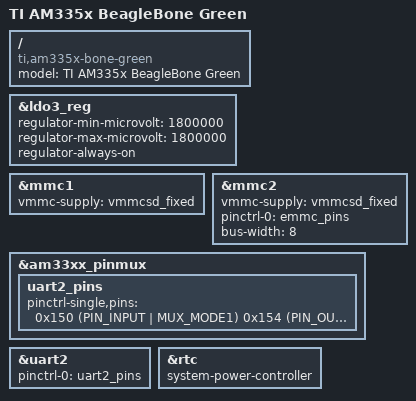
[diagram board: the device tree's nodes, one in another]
// SPDX-License-Identifier: GPL-2.0-only
/*
 * Copyright (C) 2012 Texas Instruments Incorporated - http://www.ti.com/
 */
/dts-v1/;

#include "am33xx.dtsi"
#include "am335x-bone-common.dtsi"

/ {
	model = "TI AM335x BeagleBone Green";
	compatible = "ti,am335x-bone-green", "ti,am335x-bone-black", "ti,am335x-bone", "ti,am33xx";
};

&ldo3_reg {
	regulator-min-microvolt = <1800000>;
	regulator-max-microvolt = <1800000>;
	regulator-always-on;
};

&mmc1 {
	vmmc-supply = <&vmmcsd_fixed>;
};

&mmc2 {
	vmmc-supply = <&vmmcsd_fixed>;
	pinctrl-names = "default";
	pinctrl-0 = <&emmc_pins>;
	bus-width = <8>;
	status = "okay";
};

&am33xx_pinmux {
	uart2_pins: uart2_pins {
		pinctrl-single,pins = <
			0x150 (PIN_INPUT | MUX_MODE1)	/* spi0_sclk.uart2_rxd */
			0x154 (PIN_OUTPUT | MUX_MODE1)	/* spi0_d0.uart2_txd */
		>;
	};
};

&uart2 {
	pinctrl-names = "default";
	pinctrl-0 = <&uart2_pins>;
	status = "okay";
};

&rtc {
	system-power-controller;
};
